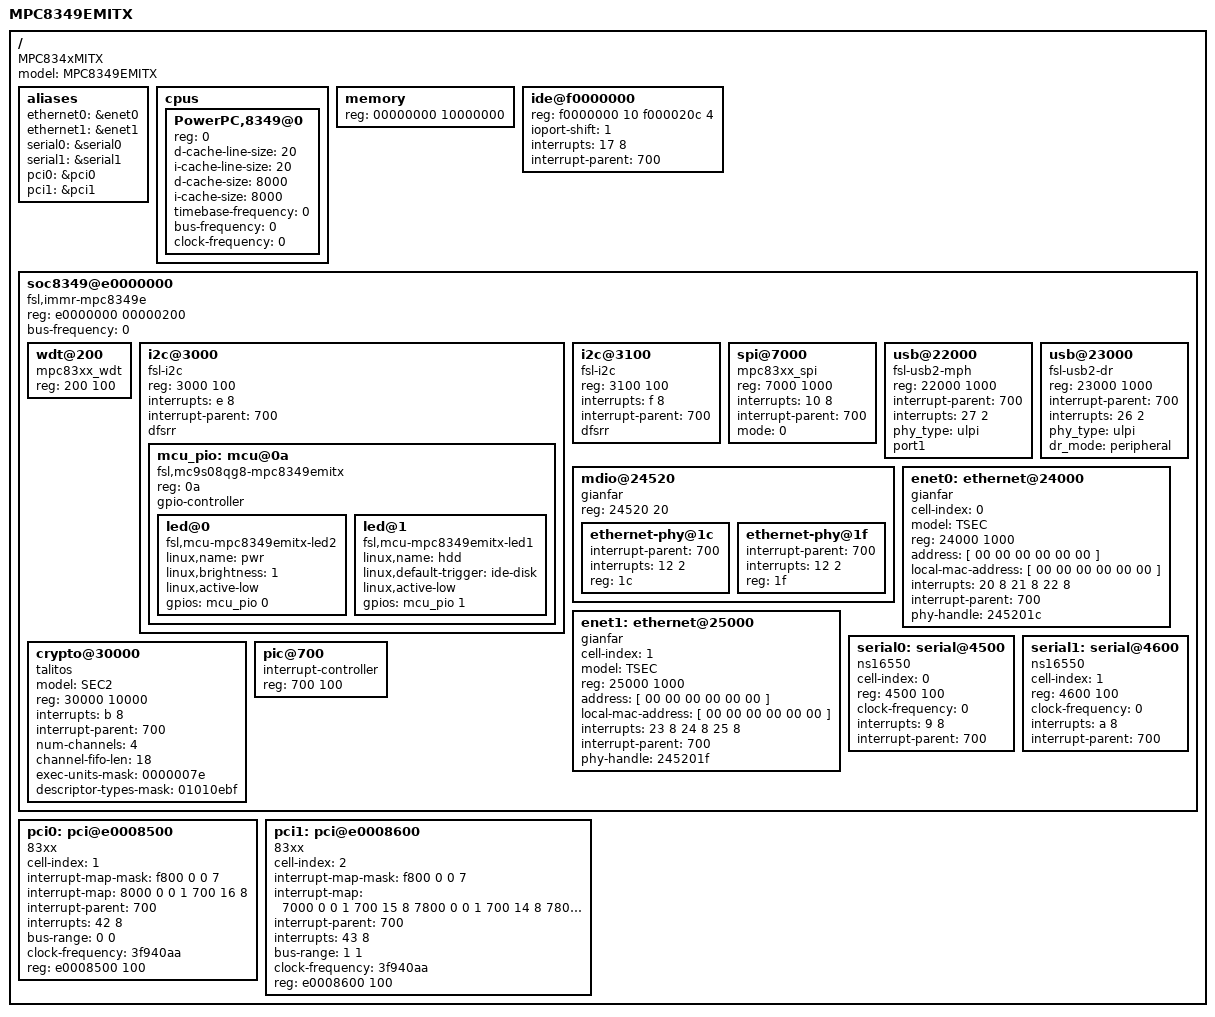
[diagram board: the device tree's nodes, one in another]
/*
 * MPC8349E-mITX Device Tree Source
 *
 * Copyright 2006 Freescale Semiconductor Inc.
 *
 * This program is free software; you can redistribute it and/or modify it
 * under the terms of the GNU General Public License as published by the
 * Free Software Foundation; either version 2 of the License, or (at your
 * option) any later version.
 */
/ {
	model = "MPC8349EMITX";
	compatible = "MPC834xMITX";
	#address-cells = <1>;
	#size-cells = <1>;

	aliases {
		ethernet0 = &enet0;
		ethernet1 = &enet1;
		serial0 = &serial0;
		serial1 = &serial1;
		pci0 = &pci0;
		pci1 = &pci1;
	};

	cpus {
		#address-cells = <1>;
		#size-cells = <0>;

		PowerPC,8349@0 {
			device_type = "cpu";
			reg = <0>;
			d-cache-line-size = <20>;
			i-cache-line-size = <20>;
			d-cache-size = <8000>;
			i-cache-size = <8000>;
			timebase-frequency = <0>;	// from bootloader
			bus-frequency = <0>;		// from bootloader
			clock-frequency = <0>;		// from bootloader
		};
	};

	memory {
		device_type = "memory";
		reg = <00000000 10000000>;
	};

	ide@f0000000 {
		reg = <f0000000 10 f000020c 4>;
		ioport-shift = <1>;
		interrupts = <17 8>;
		interrupt-parent = <700>;
	};

	soc8349@e0000000 {
		#address-cells = <1>;
		#size-cells = <1>;
		compatible = "fsl,immr-mpc8349e", "fsl,immr", "fsl,soc",
			     "simple-bus";
 		device_type = "soc";
		ranges = <0 e0000000 00100000>;
		reg = <e0000000 00000200>;
		bus-frequency = <0>;                    // from bootloader

		wdt@200 {
			device_type = "watchdog";
			compatible = "mpc83xx_wdt";
			reg = <200 100>;
		};

		i2c@3000 {
			device_type = "i2c";
			compatible = "fsl-i2c", "simple-bus";
			reg = <3000 100>;
			interrupts = <e 8>;
			interrupt-parent = <700>;
			dfsrr;

			mcu_pio: mcu@0a {
				#address-cells = <0>;
				#size-cells = <0>;
				#gpio-cells = <1>;
				compatible = "fsl,mc9s08qg8-mpc8349emitx",
					     "fsl,mcu-mpc8349emitx",
					     "simple-bus";
				reg = <0a>;
				gpio-controller;

				led@0 {
					compatible = "fsl,mcu-mpc8349emitx-led2",
						     "gpio-led";
					linux,name = "pwr";
					linux,brightness = <1>;
					linux,active-low;
					gpios = <&mcu_pio 0>;
				};

				led@1 {
					compatible = "fsl,mcu-mpc8349emitx-led1",
						     "gpio-led";
					linux,name = "hdd";
					linux,default-trigger = "ide-disk";
					linux,active-low;
					gpios = <&mcu_pio 1>;
				};
			};
		};

		i2c@3100 {
			device_type = "i2c";
			compatible = "fsl-i2c";
			reg = <3100 100>;
			interrupts = <f 8>;
			interrupt-parent = <700>;
			dfsrr;
		};

		spi@7000 {
			device_type = "spi";
			compatible = "mpc83xx_spi";
			reg = <7000 1000>;
			interrupts = <10 8>;
			interrupt-parent = <700>;
			mode = <0>;
		};

		usb@22000 {
			device_type = "usb";
			compatible = "fsl-usb2-mph";
			reg = <22000 1000>;
			#address-cells = <1>;
			#size-cells = <0>;
			interrupt-parent = <700>;
			interrupts = <27 2>;
			phy_type = "ulpi";
			port1;
		};

		usb@23000 {
			device_type = "usb";
			compatible = "fsl-usb2-dr";
			reg = <23000 1000>;
			#address-cells = <1>;
			#size-cells = <0>;
			interrupt-parent = <700>;
			interrupts = <26 2>;
			phy_type = "ulpi";
			dr_mode = "peripheral";
		};

		mdio@24520 {
			device_type = "mdio";
			compatible = "gianfar";
			reg = <24520 20>;
			#address-cells = <1>;
			#size-cells = <0>;
			linux,phandle = <24520>;

			/* Vitesse 8201 */
			ethernet-phy@1c {
				linux,phandle = <245201c>;
				interrupt-parent = <700>;
				interrupts = <12 2>;
				reg = <1c>;
				device_type = "ethernet-phy";
			};

			/* Vitesse 7385 */
			ethernet-phy@1f {
				linux,phandle = <245201f>;
				interrupt-parent = <700>;
				interrupts = <12 2>;
				reg = <1f>;
				device_type = "ethernet-phy";
			};
		};

		enet0: ethernet@24000 {
			cell-index = <0>;
			device_type = "network";
			model = "TSEC";
			compatible = "gianfar";
			reg = <24000 1000>;
			/*
			 * address is deprecated and will be removed
			 * in 2.6.25.  Only recent versions of
			 * U-Boot support local-mac-address, however.
			 */
			address = [ 00 00 00 00 00 00 ];
			local-mac-address = [ 00 00 00 00 00 00 ];
			interrupts = <20 8 21 8 22 8>;
			interrupt-parent = <700>;
			phy-handle = <245201c>;
		};

		enet1: ethernet@25000 {
			cell-index = <1>;
			#address-cells = <1>;
			#size-cells = <0>;
			device_type = "network";
			model = "TSEC";
			compatible = "gianfar";
			reg = <25000 1000>;
			/*
			 * address is deprecated and will be removed
			 * in 2.6.25.  Only recent versions of
			 * U-Boot support local-mac-address, however.
			 */
			address = [ 00 00 00 00 00 00 ];
			local-mac-address = [ 00 00 00 00 00 00 ];
			interrupts = <23 8 24 8 25 8>;
			interrupt-parent = <700>;
			phy-handle = <245201f>;
		};

		serial0: serial@4500 {
			cell-index = <0>;
			device_type = "serial";
			compatible = "ns16550";
			reg = <4500 100>;
			clock-frequency = <0>;		// from bootloader
			interrupts = <9 8>;
			interrupt-parent = <700>;
		};

		serial1: serial@4600 {
			cell-index = <1>;
			device_type = "serial";
			compatible = "ns16550";
			reg = <4600 100>;
			clock-frequency = <0>;		// from bootloader
			interrupts = <a 8>;
			interrupt-parent = <700>;
		};

		crypto@30000 {
			device_type = "crypto";
			model = "SEC2";
			compatible = "talitos";
			reg = <30000 10000>;
			interrupts = <b 8>;
			interrupt-parent = <700>;
			num-channels = <4>;
			channel-fifo-len = <18>;
			exec-units-mask = <0000007e>;
			descriptor-types-mask = <01010ebf>;
		};

		pic@700 {
			linux,phandle = <700>;
			interrupt-controller;
			#address-cells = <0>;
			#interrupt-cells = <2>;
			reg = <700 100>;
			device_type = "ipic";
		};
	};

	pci0: pci@e0008500 {
		cell-index = <1>;
		interrupt-map-mask = <f800 0 0 7>;
		interrupt-map = <
				/* IDSEL 0x10 - SATA */
				8000 0 0 1 700 16 8 /* SATA_INTA */
				>;
		interrupt-parent = <700>;
		interrupts = <42 8>;
		bus-range = <0 0>;
		ranges = <42000000 0 80000000 80000000 0 10000000
			  02000000 0 90000000 90000000 0 10000000
			  01000000 0 00000000 e2000000 0 01000000>;
		clock-frequency = <3f940aa>;
		#interrupt-cells = <1>;
		#size-cells = <2>;
		#address-cells = <3>;
		reg = <e0008500 100>;
		compatible = "83xx";
		device_type = "pci";
	};

	pci1: pci@e0008600 {
		cell-index = <2>;
		interrupt-map-mask = <f800 0 0 7>;
		interrupt-map = <
				/* IDSEL 0x0E - MiniPCI Slot */
				7000 0 0 1 700 15 8 /* PCI_INTA */

				/* IDSEL 0x0F - PCI Slot */
				7800 0 0 1 700 14 8 /* PCI_INTA */
				7800 0 0 2 700 15 8 /* PCI_INTB */
				 >;
		interrupt-parent = <700>;
		interrupts = <43 8>;
		bus-range = <1 1>;
		ranges = <42000000 0 a0000000 a0000000 0 10000000
			  02000000 0 b0000000 b0000000 0 10000000
			  01000000 0 00000000 e3000000 0 01000000>;
		clock-frequency = <3f940aa>;
		#interrupt-cells = <1>;
		#size-cells = <2>;
		#address-cells = <3>;
		reg = <e0008600 100>;
		compatible = "83xx";
		device_type = "pci";
	};
};
